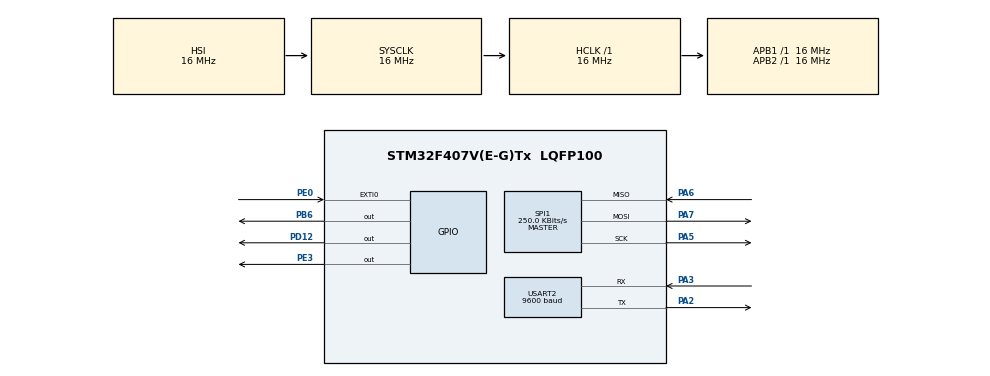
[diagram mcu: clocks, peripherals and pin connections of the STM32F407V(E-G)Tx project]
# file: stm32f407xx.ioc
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Mcu.Family=STM32F4
PA6.Mode=Full_Duplex_Master
RCC.CortexFreq_Value=16000000
PA7.Mode=Full_Duplex_Master
SPI1.VirtualType=VM_MASTER
SPI1.CLKPhase=SPI_PHASE_2EDGE
USART2.BaudRate=9600
ProjectManager.StackSize=0x400
PA3.Mode=Asynchronous
ProjectManager.TargetToolchain=STM32CubeIDE
SPI1.Direction=SPI_DIRECTION_2LINES
PB6.Signal=GPIO_Output
SPI1.CalculateBaudRate=250.0 KBits/s
RCC.LSE_VALUE=32768
RCC.AHBFreq_Value=16000000
PE3.PinState=GPIO_PIN_SET
PA5.Signal=SPI1_SCK
RCC.HSE_VALUE=25000000
board=custom
RCC.VCOOutputFreq_Value=192000000
NVIC.SPI1_IRQn=true\:0\:0\:false\:false\:true\:true\:true
RCC.APB2Freq_Value=16000000
SPI1.Mode=SPI_MODE_MASTER
Mcu.Name=STM32F407V(E-G)Tx
PE0.Signal=GPXTI0
PA2.Signal=USART2_TX
NVIC.EXTI0_IRQn=true\:0\:0\:false\:false\:true\:true\:true
RCC.SYSCLKFreq_VALUE=16000000
Mcu.Package=LQFP100
PA6.Signal=SPI1_MISO
USART2.VirtualMode=VM_ASYNC
PD12.Signal=GPIO_Output
ProjectManager.HeapSize=0x200
RCC.HSI_VALUE=16000000
NVIC.PriorityGroup=NVIC_PRIORITYGROUP_4
PA2.Mode=Asynchronous
PE3.Signal=GPIO_Output
RCC.APB1Freq_Value=16000000
SPI1.BaudRatePrescaler=SPI_BAUDRATEPRESCALER_64
PA3.Signal=USART2_RX
PA5.Mode=Full_Duplex_Master
PA7.Signal=SPI1_MOSI

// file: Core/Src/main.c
/* USER CODE BEGIN Header */
/**
  ******************************************************************************
  * @file           : main.c
  * @brief          : Main program body
  ******************************************************************************
  * @attention
  *
  * <h2><center>&copy; Copyright (c) 2021 STMicroelectronics.
  * All rights reserved.</center></h2>
  *
  * This software component is licensed by ST under BSD 3-Clause license,
  * the "License"; You may not use this file except in compliance with the
  * License. You may obtain a copy of the License at:
  *                        opensource.org/licenses/BSD-3-Clause
  *
  ******************************************************************************
  */
/* USER CODE END Header */
#include <string.h>
#include "main.h"

SPI_HandleTypeDef hspi1;

UART_HandleTypeDef huart2;

void SystemClock_Config(void);
static void MX_GPIO_Init(void);
static void MX_SPI1_Init(void);
static void MX_USART2_UART_Init(void);

int main(void)
{
//	uint8_t rxBuffer[6];
	uint8_t txBuffer[] = "discovery";
	HAL_Init();

	SystemClock_Config();

	MX_GPIO_Init();
	MX_SPI1_Init();
	MX_USART2_UART_Init();

	while (1)
	{
		  HAL_GPIO_TogglePin(GPIOD, GPIO_PIN_12);

		  HAL_GPIO_WritePin(GPIOB, GPIO_PIN_6, RESET);

		  HAL_SPI_Transmit(&hspi1, txBuffer, strlen((char *)txBuffer), HAL_MAX_DELAY);

		  HAL_GPIO_WritePin(GPIOB, GPIO_PIN_6, SET);

//		  HAL_UART_Transmit(&huart2, rxBuffer, 6, HAL_MAX_DELAY);

		  HAL_Delay(1000);

  }

}

/**
  * @brief This function handles SPI1 global interrupt.
  */
void SPI1_IRQHandler(void)
{
  /* USER CODE BEGIN SPI1_IRQn 0 */
	uint8_t buffer[] = "SPIHandler Finished\n\r";

  /* USER CODE END SPI1_IRQn 0 */
	HAL_SPI_IRQHandler(&hspi1);
  /* USER CODE BEGIN SPI1_IRQn 1 */
	HAL_UART_Transmit(&huart2, buffer, strlen((char *)buffer), HAL_MAX_DELAY);

	SPI1->CR2 &= ~(1 << 6);

  /* USER CODE END SPI1_IRQn 1 */
}

void SystemClock_Config(void)
{
  RCC_OscInitTypeDef RCC_OscInitStruct = {0};
  RCC_ClkInitTypeDef RCC_ClkInitStruct = {0};

  /** Configure the main internal regulator output voltage
  */
  __HAL_RCC_PWR_CLK_ENABLE();
  __HAL_PWR_VOLTAGESCALING_CONFIG(PWR_REGULATOR_VOLTAGE_SCALE1);
  /** Initializes the RCC Oscillators according to the specified parameters
  * in the RCC_OscInitTypeDef structure.
  */
  RCC_OscInitStruct.OscillatorType = RCC_OSCILLATORTYPE_HSI;
  RCC_OscInitStruct.HSIState = RCC_HSI_ON;
  RCC_OscInitStruct.HSICalibrationValue = RCC_HSICALIBRATION_DEFAULT;
  RCC_OscInitStruct.PLL.PLLState = RCC_PLL_NONE;
  if (HAL_RCC_OscConfig(&RCC_OscInitStruct) != HAL_OK)
  {
    Error_Handler();
  }
  /** Initializes the CPU, AHB and APB buses clocks
  */
  RCC_ClkInitStruct.ClockType = RCC_CLOCKTYPE_HCLK|RCC_CLOCKTYPE_SYSCLK
                              |RCC_CLOCKTYPE_PCLK1|RCC_CLOCKTYPE_PCLK2;
  RCC_ClkInitStruct.SYSCLKSource = RCC_SYSCLKSOURCE_HSI;
  RCC_ClkInitStruct.AHBCLKDivider = RCC_SYSCLK_DIV1;
  RCC_ClkInitStruct.APB1CLKDivider = RCC_HCLK_DIV1;
  RCC_ClkInitStruct.APB2CLKDivider = RCC_HCLK_DIV1;

  if (HAL_RCC_ClockConfig(&RCC_ClkInitStruct, FLASH_LATENCY_0) != HAL_OK)
  {
    Error_Handler();
  }
}

static void MX_SPI1_Init(void)
{

  /* SPI1 parameter configuration*/
  hspi1.Instance = SPI1;
  hspi1.Init.Mode = SPI_MODE_MASTER;
  hspi1.Init.Direction = SPI_DIRECTION_2LINES;
  hspi1.Init.DataSize = SPI_DATASIZE_8BIT;
  hspi1.Init.CLKPolarity = SPI_POLARITY_LOW;
  hspi1.Init.CLKPhase = SPI_PHASE_2EDGE;
  hspi1.Init.NSS = SPI_NSS_SOFT;
  hspi1.Init.BaudRatePrescaler = SPI_BAUDRATEPRESCALER_64;
  hspi1.Init.FirstBit = SPI_FIRSTBIT_MSB;
  hspi1.Init.TIMode = SPI_TIMODE_DISABLE;
  hspi1.Init.CRCCalculation = SPI_CRCCALCULATION_DISABLE;
  hspi1.Init.CRCPolynomial = 10;
  if (HAL_SPI_Init(&hspi1) != HAL_OK)
  {
    Error_Handler();
  }

}

static void MX_USART2_UART_Init(void)
{

  huart2.Instance = USART2;
  huart2.Init.BaudRate = 9600;
  huart2.Init.WordLength = UART_WORDLENGTH_8B;
  huart2.Init.StopBits = UART_STOPBITS_1;
  huart2.Init.Parity = UART_PARITY_NONE;
  huart2.Init.Mode = UART_MODE_TX_RX;
  huart2.Init.HwFlowCtl = UART_HWCONTROL_NONE;
  huart2.Init.OverSampling = UART_OVERSAMPLING_16;
  if (HAL_UART_Init(&huart2) != HAL_OK)
  {
    Error_Handler();
  }

}

static void MX_GPIO_Init(void)
{
  GPIO_InitTypeDef GPIO_InitStruct = {0};

  /* GPIO Ports Clock Enable */
  __HAL_RCC_GPIOE_CLK_ENABLE();
  __HAL_RCC_GPIOA_CLK_ENABLE();
  __HAL_RCC_GPIOD_CLK_ENABLE();
  __HAL_RCC_GPIOB_CLK_ENABLE();

  /*Configure GPIO pin Output Level */
  HAL_GPIO_WritePin(GPIOE, GPIO_PIN_3, GPIO_PIN_SET);

  /*Configure GPIO pin Output Level */
  HAL_GPIO_WritePin(GPIOD, GPIO_PIN_12, GPIO_PIN_RESET);

  /*Configure GPIO pin Output Level */
  HAL_GPIO_WritePin(GPIOB, GPIO_PIN_6, GPIO_PIN_RESET);

  /*Configure GPIO pin : PE3 */
  GPIO_InitStruct.Pin = GPIO_PIN_3;
  GPIO_InitStruct.Mode = GPIO_MODE_OUTPUT_PP;
  GPIO_InitStruct.Pull = GPIO_NOPULL;
  GPIO_InitStruct.Speed = GPIO_SPEED_FREQ_LOW;
  HAL_GPIO_Init(GPIOE, &GPIO_InitStruct);

  /*Configure GPIO pin : PD12 */
  GPIO_InitStruct.Pin = GPIO_PIN_12;
  GPIO_InitStruct.Mode = GPIO_MODE_OUTPUT_PP;
  GPIO_InitStruct.Pull = GPIO_NOPULL;
  GPIO_InitStruct.Speed = GPIO_SPEED_FREQ_LOW;
  HAL_GPIO_Init(GPIOD, &GPIO_InitStruct);

  /*Configure GPIO pin : PB6 */
  GPIO_InitStruct.Pin = GPIO_PIN_6;
  GPIO_InitStruct.Mode = GPIO_MODE_OUTPUT_PP;
  GPIO_InitStruct.Pull = GPIO_NOPULL;
  GPIO_InitStruct.Speed = GPIO_SPEED_FREQ_LOW;
  HAL_GPIO_Init(GPIOB, &GPIO_InitStruct);

  /*Configure GPIO pin : PE0 */
  GPIO_InitStruct.Pin = GPIO_PIN_0;
  GPIO_InitStruct.Mode = GPIO_MODE_IT_RISING;
  GPIO_InitStruct.Pull = GPIO_NOPULL;
  HAL_GPIO_Init(GPIOE, &GPIO_InitStruct);

  /* EXTI interrupt init*/
  HAL_NVIC_SetPriority(EXTI0_IRQn, 0, 0);
  HAL_NVIC_EnableIRQ(EXTI0_IRQn);

}

void Error_Handler(void)
{
  __disable_irq();
  while (1)
  {
  }
}

/************************ (C) COPYRIGHT STMicroelectronics *****END OF FILE****/
